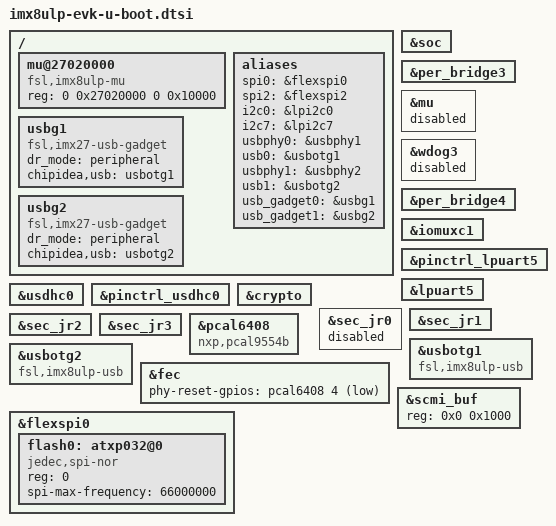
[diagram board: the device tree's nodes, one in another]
// SPDX-License-Identifier: (GPL-2.0 OR MIT)
/*
 * Copyright 2021 NXP
 */

#include "imx8ulp-u-boot.dtsi"

/ {
	mu@27020000 {
		compatible = "fsl,imx8ulp-mu";
		reg = <0 0x27020000 0 0x10000>;
		status = "okay";
		bootph-all;
	};

	aliases {
		spi0 = &flexspi0;
		spi2 = &flexspi2;
		i2c0 = &lpi2c0;
		i2c7 = &lpi2c7;
		usbphy0 = &usbphy1;
		usb0 = &usbotg1;
		usbphy1 = &usbphy2;
		usb1 = &usbotg2;
		usb_gadget0 = &usbg1;
		usb_gadget1 = &usbg2;
	};

	usbg1: usbg1 {
		compatible = "fsl,imx27-usb-gadget";
		dr_mode = "peripheral";
		chipidea,usb = <&usbotg1>;
		status = "okay";
	};

	usbg2: usbg2 {
		compatible = "fsl,imx27-usb-gadget";
		dr_mode = "peripheral";
		chipidea,usb = <&usbotg2>;
		status = "okay";
	};
};

&soc {
	bootph-all;
};

&per_bridge3 {
	bootph-all;
};

&mu {
	status = "disabled";
};

&wdog3 {
	status = "disabled";
};

&per_bridge4 {
	bootph-all;
	bootph-pre-ram;
};

&iomuxc1 {
	bootph-all;
};

&pinctrl_lpuart5 {
	bootph-all;
};

&lpuart5 {
	bootph-all;
};

&usdhc0 {
	bootph-pre-ram;
};

&pinctrl_usdhc0 {
	bootph-pre-ram;
};

&crypto {
	bootph-pre-ram;
};

&sec_jr0 {
	bootph-pre-ram;
	status = "disabled";
};

&sec_jr1 {
	bootph-pre-ram;
};

&sec_jr2 {
	bootph-pre-ram;
};

&sec_jr3 {
	bootph-pre-ram;
};

&usbotg1 {
	compatible = "fsl,imx8ulp-usb", "fsl,imx7ulp-usb", "fsl,imx27-usb";
};

&usbotg2 {
	compatible = "fsl,imx8ulp-usb", "fsl,imx7ulp-usb", "fsl,imx27-usb";
};

&pcal6408 {
	compatible = "nxp,pcal9554b", "ti,tca6408";
};

&fec {
	phy-reset-gpios = <&pcal6408 4 GPIO_ACTIVE_LOW>;
};

&scmi_buf {
	reg = <0x0 0x1000>; /* Align page size */
};

&flexspi0 {
	status = "okay";

	flash0: atxp032@0 {
		reg = <0>;
		#address-cells = <1>;
		#size-cells = <1>;
		compatible = "jedec,spi-nor";
		spi-max-frequency = <66000000>;
	};
};
